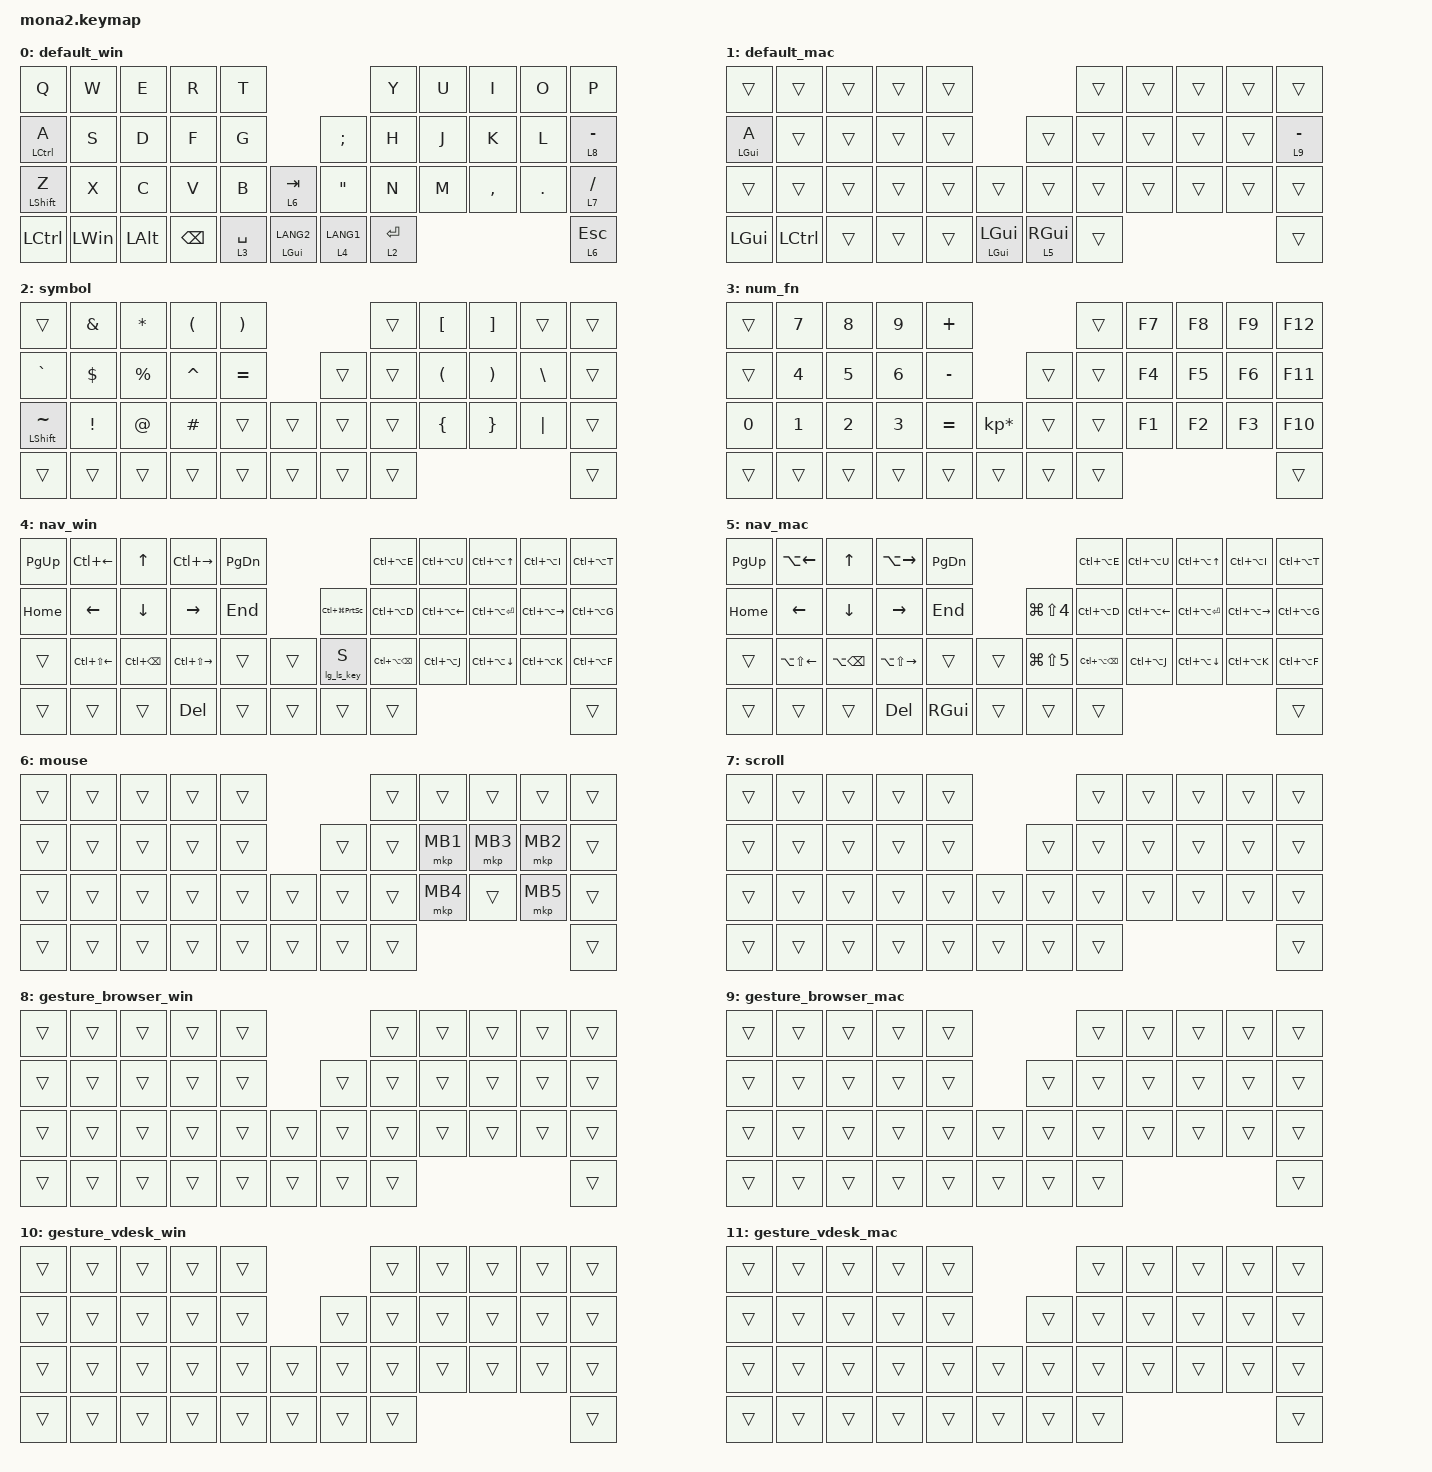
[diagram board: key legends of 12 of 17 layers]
#include <behaviors.dtsi>
#include <dt-bindings/zmk/bt.h>
#include <dt-bindings/zmk/keys.h>
#include <dt-bindings/zmk/outputs.h>
#include <dt-bindings/zmk/pointing.h>
#include "gesture/gesture_browser_win.dtsi"
#include "gesture/gesture_browser_mac.dtsi"
#include "gesture/gesture_vdesk_win.dtsi"
#include "gesture/gesture_vdesk_mac.dtsi"
#include "gesture/gesture_general_win.dtsi"
#include "gesture/gesture_general_mac.dtsi"
#include "gesture/gesture_app_switch.dtsi"

#define ZMK_POINTING_DEFAULT_SCRL_VAL 100
#define MOUSE 6
#define POINTER_FAST 16

&mt {
    flavor = "balanced";
    quick-tap-ms = <0>;
};

&lt {
    quick-tap-ms = <200>;
    flavor = "balanced";
};

/ {
    combos {
        compatible = "zmk,combos";

        app_sw_mac {
            bindings = <&app_sw_mac>;
            key-positions = <19 20>;
            layers = <1>;
            timeout-ms = <100>;
            slow-release;
        };

        app_sw_win {
            bindings = <&app_sw_win>;
            key-positions = <19 20>;
            layers = <0>;
            timeout-ms = <100>;
            slow-release;
        };

        // .+/: 仮想デスクトップジェスチャー
        // W+Eは通常入力中に誤爆しやすいため使わない
        vdesk_win {
            bindings = <&mo 10>;
            key-positions = <31 32>;
            layers = <0>;
            timeout-ms = <100>;
            slow-release;
        };

        vdesk_mac {
            bindings = <&mo 11>;
            key-positions = <31 32>;
            layers = <1>;
            timeout-ms = <100>;
            slow-release;
        };

        general_mac {
            bindings = <&mo 13>;
            key-positions = <8 9>;
            layers = <1>;
            timeout-ms = <100>;
            slow-release;
        };

        general_win {
            bindings = <&mo 12>;
            key-positions = <8 9>;
            layers = <0>;
            timeout-ms = <100>;
            slow-release;
        };

        BT_layer {
            bindings = <&mo 15>;
            key-positions = <38 39>;
            // 16(POINTER_FAST)を含める: トグルON中は最上位レイヤーが16になるため、
            // ここに無いとBTレイヤーへ入れず高速ポインタを解除できなくなる
            layers = <0 1 16>;
            timeout-ms = <250>;
            slow-release;
        };

        Delete {
            bindings = <&kp DEL>;
            key-positions = <36 39>;
            layers = <0 1>;
            timeout-ms = <100>;
        };

        Select_All_mac {
            bindings = <&kp LG(A)>;
            key-positions = <0 10>;
            layers = <1>;
            timeout-ms = <100>;
        };

        Aqua_Voice {
            bindings = <&aqua_voice>;
            key-positions = <37 39>;
            layers = <1>;
            timeout-ms = <150>;
        };

        Typeless {
            bindings = <&typeless>;
            key-positions = <37 40>;
            layers = <1>;
            timeout-ms = <150>;
        };

        Select_All_win {
            bindings = <&kp LC(A)>;
            key-positions = <0 10>;
            layers = <0>;
            timeout-ms = <100>;
        };

        win_secure_attention {
            bindings = <&ctrl_alt_del>;
            key-positions = <33 35 36>;
            layers = <0>;
            timeout-ms = <250>;
        };
    };

    macros {
        to_layer_0: to_layer_0 {
            compatible = "zmk,behavior-macro-one-param";
            #binding-cells = <1>;
            bindings = <&tog_off 1 &macro_param_1to1 &kp MACRO_PLACEHOLDER>;
            label = "TO_LAYER_0";
        };

        to_layer_1: to_layer_1 {
            compatible = "zmk,behavior-macro-one-param";
            #binding-cells = <1>;
            bindings = <&tog_on 1 &macro_param_1to1 &kp MACRO_PLACEHOLDER>;
            label = "TO_LAYER_1";
        };

        app_sw_win: app_sw_win {
            compatible = "zmk,behavior-macro";
            wait-ms = <30>;
            tap-ms = <40>;
            #binding-cells = <0>;
            bindings
                = <&macro_press &kp LALT &mo 14>
                , <&macro_tap &kp TAB>
                , <&macro_pause_for_release>
                , <&macro_release &kp LALT &mo 14>;
            label = "APP_SW_WIN";
        };

        ctrl_alt_del: ctrl_alt_del {
            compatible = "zmk,behavior-macro";
            wait-ms = <30>;
            tap-ms = <40>;
            #binding-cells = <0>;
            bindings
                = <&macro_press &kp LCTRL &kp LALT>
                , <&macro_tap &kp DEL>
                , <&macro_release &kp LALT &kp LCTRL>;
            label = "CTRL_ALT_DEL";
        };

        lg_key: lg_key {
            compatible = "zmk,behavior-macro-one-param";
            wait-ms = <30>;
            tap-ms = <40>;
            #binding-cells = <1>;
            bindings
                = <&macro_press &kp LGUI>
                , <&macro_tap>
                , <&macro_param_1to1>
                , <&kp MACRO_PLACEHOLDER>
                , <&macro_release &kp LGUI>;
            label = "lg_key";
        };

        lc_key: lc_key {
            compatible = "zmk,behavior-macro-one-param";
            wait-ms = <30>;
            tap-ms = <40>;
            #binding-cells = <1>;
            bindings
                = <&macro_press &kp LCTRL>
                , <&macro_tap>
                , <&macro_param_1to1>
                , <&kp MACRO_PLACEHOLDER>
                , <&macro_release &kp LCTRL>;
            label = "lc_key";
        };

        la_key: la_key {
            compatible = "zmk,behavior-macro-one-param";
            wait-ms = <30>;
            tap-ms = <40>;
            #binding-cells = <1>;
            bindings
                = <&macro_press &kp LALT>
                , <&macro_tap>
                , <&macro_param_1to1>
                , <&kp MACRO_PLACEHOLDER>
                , <&macro_release &kp LALT>;
            label = "la_key";
        };

        ls_key: ls_key {
            compatible = "zmk,behavior-macro-one-param";
            wait-ms = <30>;
            tap-ms = <40>;
            #binding-cells = <1>;
            bindings
                = <&macro_press &kp LSHFT>
                , <&macro_tap>
                , <&macro_param_1to1>
                , <&kp MACRO_PLACEHOLDER>
                , <&macro_release &kp LSHFT>;
            label = "ls_key";
        };

        lc_ls_key: lc_ls_key {
            compatible = "zmk,behavior-macro-one-param";
            wait-ms = <30>;
            tap-ms = <40>;
            #binding-cells = <1>;
            bindings
                = <&macro_press &kp LCTRL &kp LSHFT>
                , <&macro_tap>
                , <&macro_param_1to1>
                , <&kp MACRO_PLACEHOLDER>
                , <&macro_release &kp LSHFT &kp LCTRL>;
            label = "lc_ls_key";
        };

        lg_ls_key: lg_ls_key {
            compatible = "zmk,behavior-macro-one-param";
            wait-ms = <30>;
            tap-ms = <40>;
            #binding-cells = <1>;
            bindings
                = <&macro_press &kp LGUI &kp LSHFT>
                , <&macro_tap>
                , <&macro_param_1to1>
                , <&kp MACRO_PLACEHOLDER>
                , <&macro_release &kp LSHFT &kp LGUI>;
            label = "lg_ls_key";
        };

        lg_lc_key: lg_lc_key {
            compatible = "zmk,behavior-macro-one-param";
            wait-ms = <30>;
            tap-ms = <40>;
            #binding-cells = <1>;
            bindings
                = <&macro_press &kp LGUI &kp LCTRL>
                , <&macro_tap>
                , <&macro_param_1to1>
                , <&kp MACRO_PLACEHOLDER>
                , <&macro_release &kp LCTRL &kp LGUI>;
            label = "lg_lc_key";
        };

        lg_la_key: lg_la_key {
            compatible = "zmk,behavior-macro-one-param";
            wait-ms = <30>;
            tap-ms = <40>;
            #binding-cells = <1>;
            bindings
                = <&macro_press &kp LGUI &kp LALT>
                , <&macro_tap>
                , <&macro_param_1to1>
                , <&kp MACRO_PLACEHOLDER>
                , <&macro_release &kp LALT &kp LGUI>;
            label = "lg_la_key";
        };

        lg_lc_ls_key: lg_lc_ls_key {
            compatible = "zmk,behavior-macro-one-param";
            wait-ms = <30>;
            tap-ms = <40>;
            #binding-cells = <1>;
            bindings
                = <&macro_press &kp LGUI &kp LCTRL &kp LSHFT>
                , <&macro_tap>
                , <&macro_param_1to1>
                , <&kp MACRO_PLACEHOLDER>
                , <&macro_release &kp LSHFT &kp LCTRL &kp LGUI>;
            label = "lg_lc_ls_key";
        };

        aqua_voice: aqua_voice {
            compatible = "zmk,behavior-macro";
            #binding-cells = <0>;
            bindings
                = <&macro_press &kp RGUI &kp RALT>
                , <&macro_pause_for_release>
                , <&macro_release &kp RALT &kp RGUI>;
            label = "AQUA_VOICE";
        };

        typeless: typeless {
            compatible = "zmk,behavior-macro";
            #binding-cells = <0>;
            bindings
                = <&macro_press &kp LALT &kp LGUI>
                , <&macro_pause_for_release>
                , <&macro_release &kp LGUI &kp LALT>;
            label = "TYPELESS";
        };

        bt_0: bt_0 {
            compatible = "zmk,behavior-macro";
            #binding-cells = <0>;
            bindings = <&out OUT_BLE>, <&bt BT_SEL 0>;
            label = "BT_0";
        };

        bt_1: bt_1 {
            compatible = "zmk,behavior-macro";
            #binding-cells = <0>;
            bindings = <&out OUT_BLE>, <&bt BT_SEL 1>;
            label = "BT_1";
        };

        bt_2: bt_2 {
            compatible = "zmk,behavior-macro";
            #binding-cells = <0>;
            bindings = <&out OUT_BLE>, <&bt BT_SEL 2>;
            label = "BT_2";
        };

        bt_3: bt_3 {
            compatible = "zmk,behavior-macro";
            #binding-cells = <0>;
            bindings = <&out OUT_BLE>, <&bt BT_SEL 3>;
            label = "BT_3";
        };

        bt_4: bt_4 {
            compatible = "zmk,behavior-macro";
            #binding-cells = <0>;
            bindings = <&out OUT_BLE>, <&bt BT_SEL 4>;
            label = "BT_4";
        };

        app_sw_mac: app_sw_mac {
            compatible = "zmk,behavior-macro";
            wait-ms = <30>;
            tap-ms = <40>;
            #binding-cells = <0>;
            bindings
                = <&macro_press &kp LGUI &mo 14>
                , <&macro_tap &kp TAB>
                , <&macro_pause_for_release>
                , <&macro_release &kp LGUI &mo 14>;
            label = "APP_SW_MAC";
        };

        win_mode: win_mode {
            compatible = "zmk,behavior-macro";
            wait-ms = <0>;
            tap-ms = <0>;
            #binding-cells = <0>;
            bindings = <&macro_release &kp LALT &kp LGUI>
                     , <&macro_tap &tog_on 1>
                     , <&tog_off 1>;
            label = "WIN_MODE";
        };

        mac_mode: mac_mode {
            compatible = "zmk,behavior-macro";
            wait-ms = <0>;
            tap-ms = <0>;
            #binding-cells = <0>;
            bindings = <&macro_release &kp LALT &kp LGUI>
                     , <&macro_tap &tog_off 1>
                     , <&tog_on 1>;
            label = "MAC_MODE";
        };

        exit_AML: exit_AML {
            compatible = "zmk,behavior-macro";
            wait-ms = <0>;
            tap-ms = <0>;
            #binding-cells = <0>;
            bindings = <&tog_off MOUSE>;
            label = "exit_AML";
        };

        kp_exit_AML: kp_exit_AML {
            compatible = "zmk,behavior-macro-one-param";
            wait-ms = <0>;
            tap-ms = <0>;
            #binding-cells = <1>;
            bindings = <&macro_param_1to1 &kp MACRO_PLACEHOLDER &exit_AML>;
            label = "KP_exit_AML";
        };

    };

    behaviors {
        lt_to_layer_0: lt_to_layer_0 {
            compatible = "zmk,behavior-hold-tap";
            label = "LAYER_TAP_TO_0";
            #binding-cells = <2>;
            tapping-term-ms = <230>;
            quick-tap-ms = <200>;
            flavor = "tap-preferred";
            bindings = <&mo>, <&to_layer_0>;
            // LANG2(38)を除外: LANG2と同時押しの場合holdを発動しない → BTコンボ優先
            hold-trigger-key-positions = <0 1 2 3 4 5 6 7 8 9 10 11 12 13 14 15 16 17 18 19 20 21 22 23 24 25 26 27 28 29 30 31 32 33 34 35 36 37 40 41>;
        };

        lt_to_layer_1: lt_to_layer_1 {
            compatible = "zmk,behavior-hold-tap";
            label = "LAYER_TAP_TO_1";
            #binding-cells = <2>;
            tapping-term-ms = <230>;
            quick-tap-ms = <200>;
            flavor = "tap-preferred";
            bindings = <&mo>, <&to_layer_1>;
            hold-trigger-key-positions = <0 1 2 3 4 5 6 7 8 9 10 11 12 13 14 15 16 17 18 19 20 21 22 23 24 25 26 27 28 29 30 31 32 33 34 35 36 37 40 41>;
        };

        scroll_up_down: mouse_wheel_up_down {
            compatible = "zmk,behavior-sensor-rotate";
            #sensor-binding-cells = <0>;
            tap-ms = <20>;
            bindings = <&msc SCRL_DOWN>, <&msc SCRL_UP>;
        };

        scroll_right_left: mouse_wheel_right_left {
            compatible = "zmk,behavior-sensor-rotate";
            #sensor-binding-cells = <0>;
            tap-ms = <20>;
            bindings = <&msc SCRL_LEFT>, <&msc SCRL_RIGHT>;
        };

        nav_tabs_win_steps: nav_tabs_win_steps {
            compatible = "zmk,behavior-sensor-rotate";
            #sensor-binding-cells = <0>;
            tap-ms = <40>;
            bindings = <&lc_key TAB>, <&lc_ls_key TAB>;
        };

        nav_tabs_mac_steps: nav_tabs_mac_steps {
            compatible = "zmk,behavior-sensor-rotate";
            #sensor-binding-cells = <0>;
            tap-ms = <40>;
            bindings = <&lg_ls_key RBKT>, <&lg_ls_key LBKT>;
        };

        browser_zoom_win_steps: browser_zoom_win_steps {
            compatible = "zmk,behavior-sensor-rotate";
            #sensor-binding-cells = <0>;
            tap-ms = <40>;
            bindings = <&lc_key MINUS>, <&lc_ls_key EQUAL>;
        };

        browser_zoom_mac_steps: browser_zoom_mac_steps {
            compatible = "zmk,behavior-sensor-rotate";
            #sensor-binding-cells = <0>;
            tap-ms = <40>;
            bindings = <&lg_key MINUS>, <&lg_key EQUAL>;
        };

        vdesk_win_steps: vdesk_win_steps {
            compatible = "zmk,behavior-sensor-rotate";
            #sensor-binding-cells = <0>;
            tap-ms = <40>;
            bindings = <&lg_lc_key LEFT>, <&lg_lc_key RIGHT>;
        };

        vdesk_mac_steps: vdesk_mac_steps {
            compatible = "zmk,behavior-sensor-rotate";
            #sensor-binding-cells = <0>;
            tap-ms = <40>;
            bindings = <&lc_key LEFT>, <&lc_key RIGHT>;
        };

        general_win_steps: general_win_steps {
            compatible = "zmk,behavior-sensor-rotate";
            #sensor-binding-cells = <0>;
            tap-ms = <40>;
            bindings = <&la_key LEFT>, <&la_key RIGHT>;
        };

        window_zoom_win_steps: window_zoom_win_steps {
            compatible = "zmk,behavior-sensor-rotate";
            #sensor-binding-cells = <0>;
            tap-ms = <40>;
            bindings = <&lg_key MINUS>, <&lg_key EQUAL>;
        };

        window_zoom_mac_steps: window_zoom_mac_steps {
            compatible = "zmk,behavior-sensor-rotate";
            #sensor-binding-cells = <0>;
            tap-ms = <40>;
            bindings = <&lg_la_key MINUS>, <&lg_la_key EQUAL>;
        };

        general_mac_steps: general_mac_steps {
            compatible = "zmk,behavior-sensor-rotate";
            #sensor-binding-cells = <0>;
            tap-ms = <40>;
            bindings = <&lg_key LEFT>, <&lg_key RIGHT>;
        };

        app_switch_steps: app_switch_steps {
            compatible = "zmk,behavior-sensor-rotate";
            #sensor-binding-cells = <0>;
            tap-ms = <40>;
            bindings = <&ls_key TAB>, <&kp TAB>;
        };

        tog_off: toggle_layer_off {
            compatible = "zmk,behavior-toggle-layer";
            #binding-cells = <1>;
            display-name = "Toggle Layer Off";
            toggle-mode = "off";
        };

        tog_on: toggle_layer_on {
            compatible = "zmk,behavior-toggle-layer";
            #binding-cells = <1>;
            display-name = "Toggle Layer On";
            toggle-mode = "on";
        };

        mt_exit_AML_on_tap: mt_exit_AML_on_tap {
            compatible = "zmk,behavior-hold-tap";
            label = "MT_exit_AML_ON_TAP";
            bindings = <&kp>, <&kp_exit_AML>;

            #binding-cells = <2>;
            tapping-term-ms = <200>;
            flavor = "balanced";
            quick-tap-ms = <200>;
        };

        mt_lang2: mt_lang2 {
            compatible = "zmk,behavior-hold-tap";
            label = "BT_SAFE_LANG2";
            bindings = <&kp>, <&kp>;

            #binding-cells = <2>;
            tapping-term-ms = <200>;
            flavor = "balanced";
            quick-tap-ms = <175>;
            // LANG1(39)を除外: LANG2を先に押してもGUI holdへ解決させず、BTコンボを優先する
            hold-trigger-key-positions = <0 1 2 3 4 5 6 7 8 9 10 11 12 13 14 15 16 17 18 19 20 21 22 23 24 25 26 27 28 29 30 31 32 33 34 35 36 37 40 41>;
        };

    };

    keymap {
        compatible = "zmk,keymap";

        // Layer 0: default_win
        default_win {
            bindings = <
&kp Q                             &kp W         &kp E         &kp R        &kp T                                                     &kp Y        &kp U  &kp I      &kp O    &kp P
&mt_exit_AML_on_tap LCTRL A       &kp S         &kp D         &kp F        &kp G                                  &kp SEMICOLON      &kp H        &kp J  &kp K      &kp L    &lt 8 MINUS
&mt_exit_AML_on_tap LEFT_SHIFT Z  &kp X         &kp C         &kp V        &kp B        &lt 6 TAB                 &kp DOUBLE_QUOTES  &kp N        &kp M  &kp COMMA  &kp DOT  &lt 7 SLASH
&kp LCTRL                         &kp LEFT_WIN  &kp LEFT_ALT  &kp BACKSPACE  &lt 3 SPACE  &mt_lang2 LGUI LANG2    &lt_to_layer_0 4 LANG1  &lt 2 ENTER                             &lt 6 ESCAPE
            >;

            sensor-bindings = <&scroll_up_down>;
        };

        // Layer 1: default_mac
        // Layer 0に重ねるMacベース。OS差分だけ上書きし、同じキー操作で同じ用途に入る。
        default_mac {
            bindings = <
&trans                             &trans  &trans  &trans  &trans                             &trans  &trans  &trans  &trans  &trans
&mt_exit_AML_on_tap LGUI A         &trans  &trans  &trans  &trans    &trans                   &trans  &trans  &trans  &trans  &lt 9 MINUS
&trans                             &trans  &trans  &trans  &trans    &trans                   &trans  &trans  &trans  &trans  &trans  &trans
&kp LGUI  &kp LCTRL  &trans  &trans  &trans  &mt_lang2 LGUI LGUI    &lt_to_layer_1 5 RGUI   &trans                          &trans
            >;

            sensor-bindings = <&scroll_up_down>;
        };

        symbol {
            bindings = <
&trans           &kp AMPERSAND  &kp ASTRK    &kp LEFT_PARENTHESIS  &kp RIGHT_PARENTHESIS                    &trans  &kp LEFT_BRACKET      &kp RIGHT_BRACKET      &trans         &trans
&kp GRAVE        &kp DOLLAR     &kp PERCENT  &kp CARET             &kp EQUAL                        &trans  &trans  &kp LEFT_PARENTHESIS  &kp RIGHT_PARENTHESIS  &kp BACKSLASH  &trans
&mt LSHFT TILDE  &kp EXCL       &kp AT       &kp HASH              &trans                 &trans    &trans  &trans  &kp LEFT_BRACE        &kp RIGHT_BRACE        &kp PIPE       &trans
&trans           &trans         &trans       &trans                &trans                 &trans    &trans  &trans                                                              &trans
            >;

            sensor-bindings = <&scroll_right_left>;
        };

        num_fn {
            bindings = <
&trans  &kp N7  &kp N8  &kp N9  &kp PLUS                                 &trans  &kp F7  &kp F8  &kp F9  &kp F12
&trans  &kp N4  &kp N5  &kp N6  &kp MINUS                     &trans  &trans  &kp F4  &kp F5  &kp F6  &kp F11
&kp N0  &kp N1  &kp N2  &kp N3  &kp EQUAL  &kp KP_MULTIPLY    &trans  &trans  &kp F1  &kp F2  &kp F3  &kp F10
&trans  &trans  &trans  &trans  &trans     &trans             &trans     &trans                          &trans
            >;

            sensor-bindings = <&scroll_up_down>;
        };

        // Layer 4: nav_win
        // 左側: カーソル移動 + 単語編集（nav_macと共通配置）
        //   行0: [単語←]  [↑]       [単語→]
        //   行1: [←]      [↓]       [→]
        //   行2: [選択単語←] [単語削除] [選択単語→]
        //   thumb-BS: Delete  (Zは透過→LShift: Z+W=選択単語←, Z+R=選択単語→も可)
        // 右側: AHK経由ウィンドウスナップ（nav_macと同一キーコンボ）
        //   行0: [左2/3] [上左] [上半] [上右] [右2/3]
        //   行1: [SS]  [左3]  [左半] [最大] [右半] [右3]
        //   行2:       [復元] [下左] [下半] [下右] [中央]
        // encoder: Ctrl+Tab / Ctrl+Shift+Tab for tab switching
        nav_win {
            bindings = <
&kp PAGE_UP  &kp LC(LEFT)      &kp UP_ARROW       &kp LC(RIGHT)     &kp PAGE_DOWN                                     &kp LC(LA(E))         &kp LC(LA(U))     &kp LC(LA(UP))     &kp LC(LA(I))      &kp LC(LA(T))
&kp HOME     &kp LEFT          &kp DOWN           &kp RIGHT_ARROW   &kp END                  &kp LC(LG(PRINTSCREEN))  &kp LC(LA(D))         &kp LC(LA(LEFT))  &kp LC(LA(ENTER))  &kp LC(LA(RIGHT))  &kp LC(LA(G))
&trans       &kp LC(LS(LEFT))  &kp LC(BACKSPACE)  &kp LC(LS(RIGHT)) &trans         &trans    &lg_ls_key S             &kp LC(LA(BACKSPACE)) &kp LC(LA(J))     &kp LC(LA(DOWN))   &kp LC(LA(K))      &kp LC(LA(F))
&trans       &trans            &trans             &kp DEL           &trans         &trans    &trans                   &trans                                                                         &trans
            >;

            sensor-bindings = <&nav_tabs_win_steps>;
        };

        // Layer 5: nav_mac
        // 左側: カーソル移動 + 単語編集（nav_winと完全対称）
        // 右側: Magnetウィンドウスナップ専用（3×3空間マッピング）
        nav_mac {
            bindings = <
&kp PAGE_UP  &kp LA(LEFT)  &kp UP_ARROW       &kp LA(RIGHT)    &kp PAGE_DOWN                                 &kp LC(LA(E))         &kp LC(LA(U))    &kp LC(LA(UP))     &kp LC(LA(I))    &kp LC(LA(T))
&kp HOME     &kp LEFT      &kp DOWN           &kp RIGHT_ARROW  &kp END                  &kp LG(LS(N4))       &kp LC(LA(D))         &kp LC(LA(LEFT))  &kp LC(LA(ENTER))  &kp LC(LA(RIGHT))  &kp LC(LA(G))
&trans       &kp LA(LS(LEFT))  &kp LA(BACKSPACE)  &kp LA(LS(RIGHT))  &trans         &trans    &kp LG(LS(N5))       &kp LC(LA(BACKSPACE)) &kp LC(LA(J))    &kp LC(LA(DOWN))   &kp LC(LA(K))    &kp LC(LA(F))
&trans       &trans        &trans             &kp DEL          &kp RGUI       &trans    &trans               &trans                                                               &trans
            >;

            sensor-bindings = <&nav_tabs_mac_steps>;
        };

        // Layer 6: mouse
        mouse {
            bindings = <
&trans  &trans  &trans  &trans  &trans                    &trans  &trans    &trans    &trans    &trans
&trans  &trans  &trans  &trans  &trans            &trans  &trans  &mkp MB1  &mkp MB3  &mkp MB2  &trans
&trans  &trans  &trans  &trans  &trans  &trans    &trans  &trans  &mkp MB4  &trans    &mkp MB5  &trans
&trans  &trans  &trans  &trans  &trans  &trans    &trans  &trans                                &trans
            >;

            sensor-bindings = <&scroll_up_down>;
        };

        // Layer 7: scroll
        scroll {
            bindings = <
&trans  &trans  &trans  &trans  &trans                    &trans  &trans  &trans  &trans  &trans
&trans  &trans  &trans  &trans  &trans            &trans  &trans  &trans  &trans  &trans  &trans
&trans  &trans  &trans  &trans  &trans  &trans    &trans  &trans  &trans  &trans  &trans  &trans
&trans  &trans  &trans  &trans  &trans  &trans    &trans  &trans                          &trans
            >;

            sensor-bindings = <&scroll_up_down>;
        };

        // Layer 8: gesture_browser_win
        gesture_browser_win {
            bindings = <
&trans  &trans  &trans  &trans  &trans                    &trans  &trans  &trans  &trans  &trans
&trans  &trans  &trans  &trans  &trans            &trans  &trans  &trans  &trans  &trans  &trans
&trans  &trans  &trans  &trans  &trans  &trans    &trans  &trans  &trans  &trans  &trans  &trans
&trans  &trans  &trans  &trans  &trans  &trans    &trans  &trans                          &trans
            >;

            sensor-bindings = <&browser_zoom_win_steps>;
        };

        // Layer 9: gesture_browser_mac
        gesture_browser_mac {
            bindings = <
&trans  &trans  &trans  &trans  &trans                    &trans  &trans  &trans  &trans  &trans
&trans  &trans  &trans  &trans  &trans            &trans  &trans  &trans  &trans  &trans  &trans
&trans  &trans  &trans  &trans  &trans  &trans    &trans  &trans  &trans  &trans  &trans  &trans
&trans  &trans  &trans  &trans  &trans  &trans    &trans  &trans                          &trans
            >;

            sensor-bindings = <&browser_zoom_mac_steps>;
        };

        // Layer 10: gesture_vdesk_win
        gesture_vdesk_win {
            bindings = <
&trans  &trans  &trans  &trans  &trans                    &trans  &trans  &trans  &trans  &trans
&trans  &trans  &trans  &trans  &trans            &trans  &trans  &trans  &trans  &trans  &trans
&trans  &trans  &trans  &trans  &trans  &trans    &trans  &trans  &trans  &trans  &trans  &trans
&trans  &trans  &trans  &trans  &trans  &trans    &trans  &trans                          &trans
            >;

            sensor-bindings = <&vdesk_win_steps>;
        };

        // Layer 11: gesture_vdesk_mac
        gesture_vdesk_mac {
            bindings = <
&trans  &trans  &trans  &trans  &trans                    &trans  &trans  &trans  &trans  &trans
&trans  &trans  &trans  &trans  &trans            &trans  &trans  &trans  &trans  &trans  &trans
&trans  &trans  &trans  &trans  &trans  &trans    &trans  &trans  &trans  &trans  &trans  &trans
&trans  &trans  &trans  &trans  &trans  &trans    &trans  &trans                          &trans
            >;

            sensor-bindings = <&vdesk_mac_steps>;
        };

        // Layer 12: gesture_general_win
        gesture_general_win {
            bindings = <
&trans  &trans  &trans  &trans  &trans                    &trans  &trans  &trans  &trans  &trans
&trans  &trans  &trans  &trans  &trans            &trans  &trans  &trans  &trans  &trans  &trans
&trans  &trans  &trans  &trans  &trans  &trans    &trans  &trans  &trans  &trans  &trans  &trans
&trans  &trans  &trans  &trans  &trans  &trans    &trans  &trans                          &trans
            >;

            sensor-bindings = <&window_zoom_win_steps>;
        };

        // Layer 13: gesture_general_mac
        gesture_general_mac {
            bindings = <
&trans  &trans  &trans  &trans  &trans                    &trans  &trans  &trans  &trans  &trans
&trans  &trans  &trans  &trans  &trans            &trans  &trans  &trans  &trans  &trans  &trans
&trans  &trans  &trans  &trans  &trans  &trans    &trans  &trans  &trans  &trans  &trans  &trans
&trans  &trans  &trans  &trans  &trans  &trans    &trans  &trans                          &trans
            >;

            sensor-bindings = <&window_zoom_mac_steps>;
        };

        // Layer 14: App Switcher (Win/Mac 共通)
        // コンボ [19+20] で Alt/Cmd+Tab を一度送り、Win=LALT保持、Mac=LGUI保持（マクロ側で制御）
        // トラックボール左=前のアプリ(Shift+Tab)、右=次のアプリ(Tab)
        // コンボキーを離すと修飾キーも解放され、選択中のアプリに遷移
        app_switch {
            bindings = <
&trans  &trans  &trans  &trans  &trans                    &trans  &trans  &trans  &trans  &trans
&trans  &trans  &trans  &trans  &trans            &trans  &trans  &trans  &trans  &trans  &trans
&trans  &trans  &trans  &trans  &trans  &trans    &trans  &trans  &trans  &trans  &trans  &trans
&trans  &trans  &trans  &trans  &trans  &trans    &trans  &trans                          &kp ESCAPE
            >;

            sensor-bindings = <&app_switch_steps>;
        };

        // Layer 15: bt
        // Mac base の Layer 1 より高いBT/Systemレイヤー。未使用キーは下位レイヤーへ落とさない。
        bt {
            bindings = <
&none  &win_mode  &mac_mode  &none  &none                    &bt_0  &bt_1  &bt_2  &bt_3  &bt_4
&none  &none      &none      &none  &none            &none  &tog_off POINTER_FAST  &tog_on POINTER_FAST  &none  &none  &none
&none  &none      &none      &none  &none  &none    &bootloader  &none  &none  &none  &none  &bt BT_CLR
&none  &none      &none      &none  &none  &none    &bt BT_CLR   &none                          &bt BT_CLR_ALL
            >;

            sensor-bindings = <&scroll_up_down>;
        };

        // Layer 16: pointer_fast
        pointer_fast {
            bindings = <
&trans  &trans  &trans  &trans  &trans                    &trans  &trans  &trans  &trans  &trans
&trans  &trans  &trans  &trans  &trans            &trans  &trans  &trans  &trans  &trans  &trans
&trans  &trans  &trans  &trans  &trans  &trans    &trans  &trans  &trans  &trans  &trans  &trans
&trans  &trans  &trans  &trans  &trans  &trans    &trans  &trans                          &trans
            >;

            sensor-bindings = <&scroll_up_down>;
        };

    };
};
